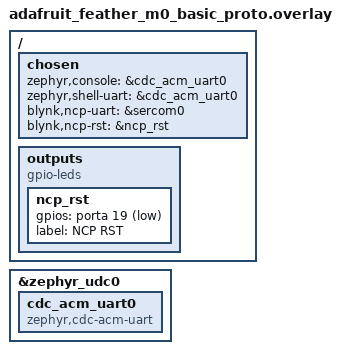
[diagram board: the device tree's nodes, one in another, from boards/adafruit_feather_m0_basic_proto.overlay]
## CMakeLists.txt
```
#
# Copyright (c) 2024 Blynk Technologies Inc.
#
# SPDX-License-Identifier: Apache-2.0
#

cmake_minimum_required(VERSION 3.20.0)
find_package(Zephyr REQUIRED HINTS $ENV{ZEPHYR_BASE})
project(blynk_over_zephyr)

target_sources(app PRIVATE src/main.c)

zephyr_get_include_directories_for_lang_as_string(       C includes)
zephyr_get_system_include_directories_for_lang_as_string(C system_includes)
zephyr_get_compile_definitions_for_lang_as_string(       C definitions)
zephyr_get_compile_options_for_lang_as_string(           C options)

set(blynk_ncp_cflags
  "${includes} ${definitions} ${options} ${system_includes}"
  )

include(ExternalProject)

# Add an external project to be able download and build the third
# party library. In this case downloading is not necessary as it has
# been committed to the repository.
set(blynk_ncp_src_dir   ${CMAKE_CURRENT_SOURCE_DIR}/../../blynk_ncp)
set(blynk_ncp_build_dir ${CMAKE_CURRENT_BINARY_DIR}/blynk_ncp)

set(BLYNK_NCP_DIR     ${blynk_ncp_build_dir}/lib)
set(BLYNK_INCLUDE_DIR ${blynk_ncp_src_dir}/src/BlynkNcpDriver/src)

if(CMAKE_GENERATOR STREQUAL "Unix Makefiles")
# https://www.gnu.org/software/make/manual/html_node/MAKE-Variable.html
set(submake "$(MAKE)")
else() # Obviously no MAKEFLAGS. Let's hope a "make" can be found somewhere.
set(submake "make")
endif()

ExternalProject_Add(
  blynk_example                 # Name for custom target
  PREFIX     ${blynk_ncp_build_dir} # Root dir for entire project
  SOURCE_DIR ${blynk_ncp_src_dir}
  BINARY_DIR ${blynk_ncp_src_dir} # This particular build system is invoked from the root
  CONFIGURE_COMMAND ""    # Skip configuring the project, e.g. with autoconf
  BUILD_COMMAND
  ${submake}
  PREFIX=${blynk_ncp_build_dir}
  CC=${CMAKE_C_COMPILER}
  AR=${CMAKE_AR}
  CFLAGS=${blynk_ncp_cflags}
  INSTALL_COMMAND ""      # This particular build system has no install command
  BUILD_BYPRODUCTS ${BLYNK_NCP_DIR}/libblynkncp.a
  DEPENDS zephyr_interface
  DEPENDS offsets_h
  )

# Create a wrapper CMake library that our app can link with
add_library(blynk_ncp_lib STATIC IMPORTED GLOBAL)
add_dependencies(
  blynk_ncp_lib
  blynk_example
  )

list(APPEND LIB_INCLUDE_DIRS ${BLYNK_INCLUDE_DIR})
list(APPEND LIB_INCLUDE_DIRS ${blynk_ncp_src_dir}/include)

set_target_properties(blynk_ncp_lib PROPERTIES IMPORTED_LOCATION             ${BLYNK_NCP_DIR}/libblynkncp.a)
set_target_properties(blynk_ncp_lib PROPERTIES INTERFACE_INCLUDE_DIRECTORIES "${LIB_INCLUDE_DIRS}")

target_link_libraries(app PUBLIC blynk_ncp_lib)
target_link_libraries(blynk_ncp_lib INTERFACE kernel)
```

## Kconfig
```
# Config options for Blynk.NCP driver

# Copyright (c) 2024 Blynk Technologies Inc.
# SPDX-License-Identifier: Apache-2.0

rsource "../../blynk_ncp/Kconfig.blynk_ncp"
source "Kconfig.zephyr"
```

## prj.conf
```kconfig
CONFIG_SERIAL=y
CONFIG_GPIO=y
CONFIG_UART_INTERRUPT_DRIVEN=y
CONFIG_UART_USE_RUNTIME_CONFIGURE=y
CONFIG_LOG=y
CONFIG_RING_BUFFER=y

CONFIG_HEAP_MEM_POOL_SIZE=2048

CONFIG_BLYNK_FIRMWARE_VERSION="0.0.0"

CONFIG_USB_BC12=y
```

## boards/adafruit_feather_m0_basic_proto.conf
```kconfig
# Copyright (c) 2024 Blynk Technologies Inc.
# SPDX-License-Identifier: Apache-2.0

# Console over USB CDC-ACM
CONFIG_SERIAL=y
CONFIG_CONSOLE=y
CONFIG_STDOUT_CONSOLE=y
CONFIG_USB_DEVICE_STACK=y
CONFIG_USB_DEVICE_MANUFACTURER="Blynk"
CONFIG_USB_DEVICE_PRODUCT="Blynk.NCP host example"
CONFIG_USB_DEVICE_PID=0x0001
CONFIG_UART_INTERRUPT_DRIVEN=y
CONFIG_UART_LINE_CTRL=y
CONFIG_USB_SELF_POWERED=n
CONFIG_USB_CDC_ACM=y
CONFIG_USB_CDC_ACM_LOG_LEVEL_OFF=y
CONFIG_USB_DEVICE_INITIALIZE_AT_BOOT=y
```

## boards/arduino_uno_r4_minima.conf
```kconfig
# Copyright (c) 2024 Blynk Technologies Inc.
# SPDX-License-Identifier: Apache-2.0

# Renesas RA4M1 has only one UART which we want to use for NCP,
# disable Console until Zephyr supports USB CDC_ACM

CONFIG_CONSOLE=y
CONFIG_UART_CONSOLE=n
```

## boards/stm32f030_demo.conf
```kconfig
# Copyright (c) 2024 Blynk Technologies Inc.
# SPDX-License-Identifier: Apache-2.0

# disable all debug and log messages
CONFIG_BOOT_BANNER=n
CONFIG_LOG=n
CONFIG_DEBUG=n
CONFIG_CONSOLE=n
CONFIG_UART_CONSOLE=n
CONFIG_STDOUT_CONSOLE=n
CONFIG_PRINTK=n
CONFIG_EARLY_CONSOLE=n
CONFIG_FAULT_DUMP=0
CONFIG_ASSERT_VERBOSE=n

# stack sizes
CONFIG_MAIN_STACK_SIZE=128
CONFIG_ISR_STACK_SIZE=256
CONFIG_SYSTEM_WORKQUEUE_STACK_SIZE=256
CONFIG_BLYNK_THERAD_STACK_SIZE=256

# buffers
CONFIG_HEAP_MEM_POOL_SIZE=0
CONFIG_BLYNK_UART_TX_BUF_SIZE=64
CONFIG_BLYNK_UART_RX_BUF_SIZE=64

# runtime and os
CONFIG_CBPRINTF_NANO=y
CONFIG_MINIMAL_LIBC=y
CONFIG_NO_RUNTIME_CHECKS=y
CONFIG_TIMEOUT_64BIT=n
CONFIG_ERRNO=n
CONFIG_TICKLESS_KERNEL=n
CONFIG_TIMESLICING=n
CONFIG_NUM_COOP_PRIORITIES=5
CONFIG_NUM_PREEMPT_PRIORITIES=10
```

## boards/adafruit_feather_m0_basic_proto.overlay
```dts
/*
 * Copyright (c) 2024 Blynk Technologies Inc.
 *
 * SPDX-License-Identifier: Apache-2.0
 */


/ {
    chosen {
        zephyr,console = &cdc_acm_uart0;
        zephyr,shell-uart = &cdc_acm_uart0;
        blynk,ncp-uart = &sercom0;
        blynk,ncp-rst = &ncp_rst;
    };

    outputs {
        compatible = "gpio-leds";
        ncp_rst: ncp_rst {
            gpios = <&porta 19 GPIO_ACTIVE_LOW>; /* D12 */
            label = "NCP RST";
        };
    };
};

&zephyr_udc0 {
    cdc_acm_uart0: cdc_acm_uart0 {
        compatible = "zephyr,cdc-acm-uart";
    };
};
```

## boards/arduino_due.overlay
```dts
/*
 * Copyright (c) 2024 Blynk Technologies Inc.
 *
 * SPDX-License-Identifier: Apache-2.0
 */


/ {
    chosen {
        zephyr,console = &usart0;
        zephyr,shell-uart = &usart0;
        blynk,ncp-uart = &uart;
        blynk,ncp-rst = &ncp_rst;
    };

    outputs {
        compatible = "gpio-leds";
        ncp_rst: ncp_rst {
            gpios = <&pioc 25 0>; /* D5 */
            label = "NCP RST";
        };
    };
};

&usart0 {
    status = "okay";
    current-speed = <115200>;

    pinctrl-0 = <&usart0_default>; /* PA10, PA11 */
    pinctrl-names = "default";
};
```

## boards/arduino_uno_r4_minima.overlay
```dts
/*
 * Copyright (c) 2024 Blynk Technologies Inc.
 *
 * SPDX-License-Identifier: Apache-2.0
 */


/ {
    chosen {
        /* Renesas RA4M1 has only one UART which we want to use for NCP,
         * disable Console until Zephyr supports USB CDC_ACM
         */
        /delete-property/ zephyr,console;
        /delete-property/ zephyr,shell-uart;

        blynk,ncp-uart = &uart2;
        blynk,ncp-rst = &ncp_rst;
    };

    outputs {
        compatible = "gpio-leds";
        ncp_rst: ncp_rst {
            gpios = <&ioport1 2 GPIO_ACTIVE_LOW>; /* D5 */
            label = "NCP RST";
        };
    };
};
```

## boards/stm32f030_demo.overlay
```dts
/*
 * Copyright (c) 2024 Blynk Technologies Inc.
 *
 * SPDX-License-Identifier: Apache-2.0
 */


/ {
    chosen {
        /delete-property/ zephyr,console;
        /delete-property/ zephyr,shell-uart;

        blynk,ncp-uart = &usart1;
        blynk,ncp-rst = &ncp_rst;
    };

    outputs {
        compatible = "gpio-leds";
        ncp_rst: ncp_rst {
            gpios = <&gpiob 1 GPIO_ACTIVE_LOW>; /* PB1 */
            label = "NCP RST";
        };
    };
};
```

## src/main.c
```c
/*
 * Copyright (c) 2024 Blynk Technologies Inc.
 *
 * SPDX-License-Identifier: Apache-2.0
 */

#include <stdio.h>
#include <stdlib.h>
#include <string.h>

#include <zephyr/kernel.h>
#include <zephyr/logging/log.h>

#include <blynk_ncp/blynk_ncp.h>

LOG_MODULE_REGISTER(blynk_example, CONFIG_LOG_DEFAULT_LEVEL);

void rpc_client_blynkVPinChange_impl(uint16_t vpin, rpc_buffer_t param)
{
    switch (vpin) {
    case 0:
        /* VPin0 to VPin1 loopback */
        rpc_blynk_virtualWrite(1 /*VPin*/, param);
        break;
    case 1:
        /* VPin0 to VPin1 loopback */
        rpc_blynk_virtualWrite(0 /*VPin*/, param);
        break;
    default:
        LOG_WRN("unknown VPIN [%hu]", vpin);
        break;
    }
}

char *format_uint32(char *s, size_t len, uint32_t x)
{
    s += len;
    *--s = 0;
    if (!x) {
        *--s = '0';
    }
    for (; x; x /= 10) {
        *--s = '0' + (x % 10);
    }
    return s;
}

int main(void)
{
#if defined(CONFIG_USB_CDC_ACM)
    // Sleep to wait for a CDC connection
    k_msleep(3000);
#endif

    LOG_INF("Blynk.NCP host example on %s", CONFIG_BOARD);
    LOG_INF("Firmware version: %s", CONFIG_BLYNK_FIRMWARE_VERSION);

    // Initialize Blynk.NCP
    if (0 != blynk_ncp_init()) {
        LOG_ERR("Can't initialize Blynk.NCP");
        return 1;
    }

    while (BLYNK_STATE_CONNECTED != blynk_ncp_get_state()) {
        k_msleep(100);
    }

    while (true) {
        const uint32_t value = k_uptime_get_32();
        LOG_DBG("Sending %u to Virtual Pin 2", value);

        char buff[16];
        char *s = format_uint32(buff, sizeof(buff), value);
        rpc_buffer_t val = {(uint8_t *)s, strlen(s)};
        rpc_blynk_virtualWrite(2 /*VPin*/, val);

        k_msleep(1000);
    }

    return 0;
}
```
